VERSION ""

NS_ :

BS_:

BU_:

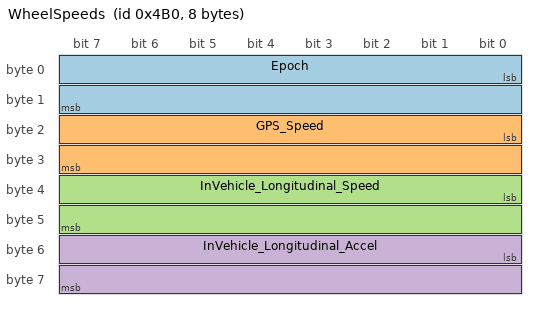
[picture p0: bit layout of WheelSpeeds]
BO_ 1200 WheelSpeeds: 8 Vector__XXX
 SG_ Epoch : 0|16@1+ (0.01,0) [0|30000] "value" Vector__XXX
 SG_ GPS_Speed : 16|16@1+ (0.01,-100) [0|2000] "kmph" Vector__XXX
 SG_ InVehicle_Longitudinal_Speed : 32|16@1+ (0.01,-100) [0|2000] "kmph" Vector__XXX
 SG_ InVehicle_Longitudinal_Accel : 48|16@1- (0.01,-100) [-2000|2000] "axis" Vector__XXX
